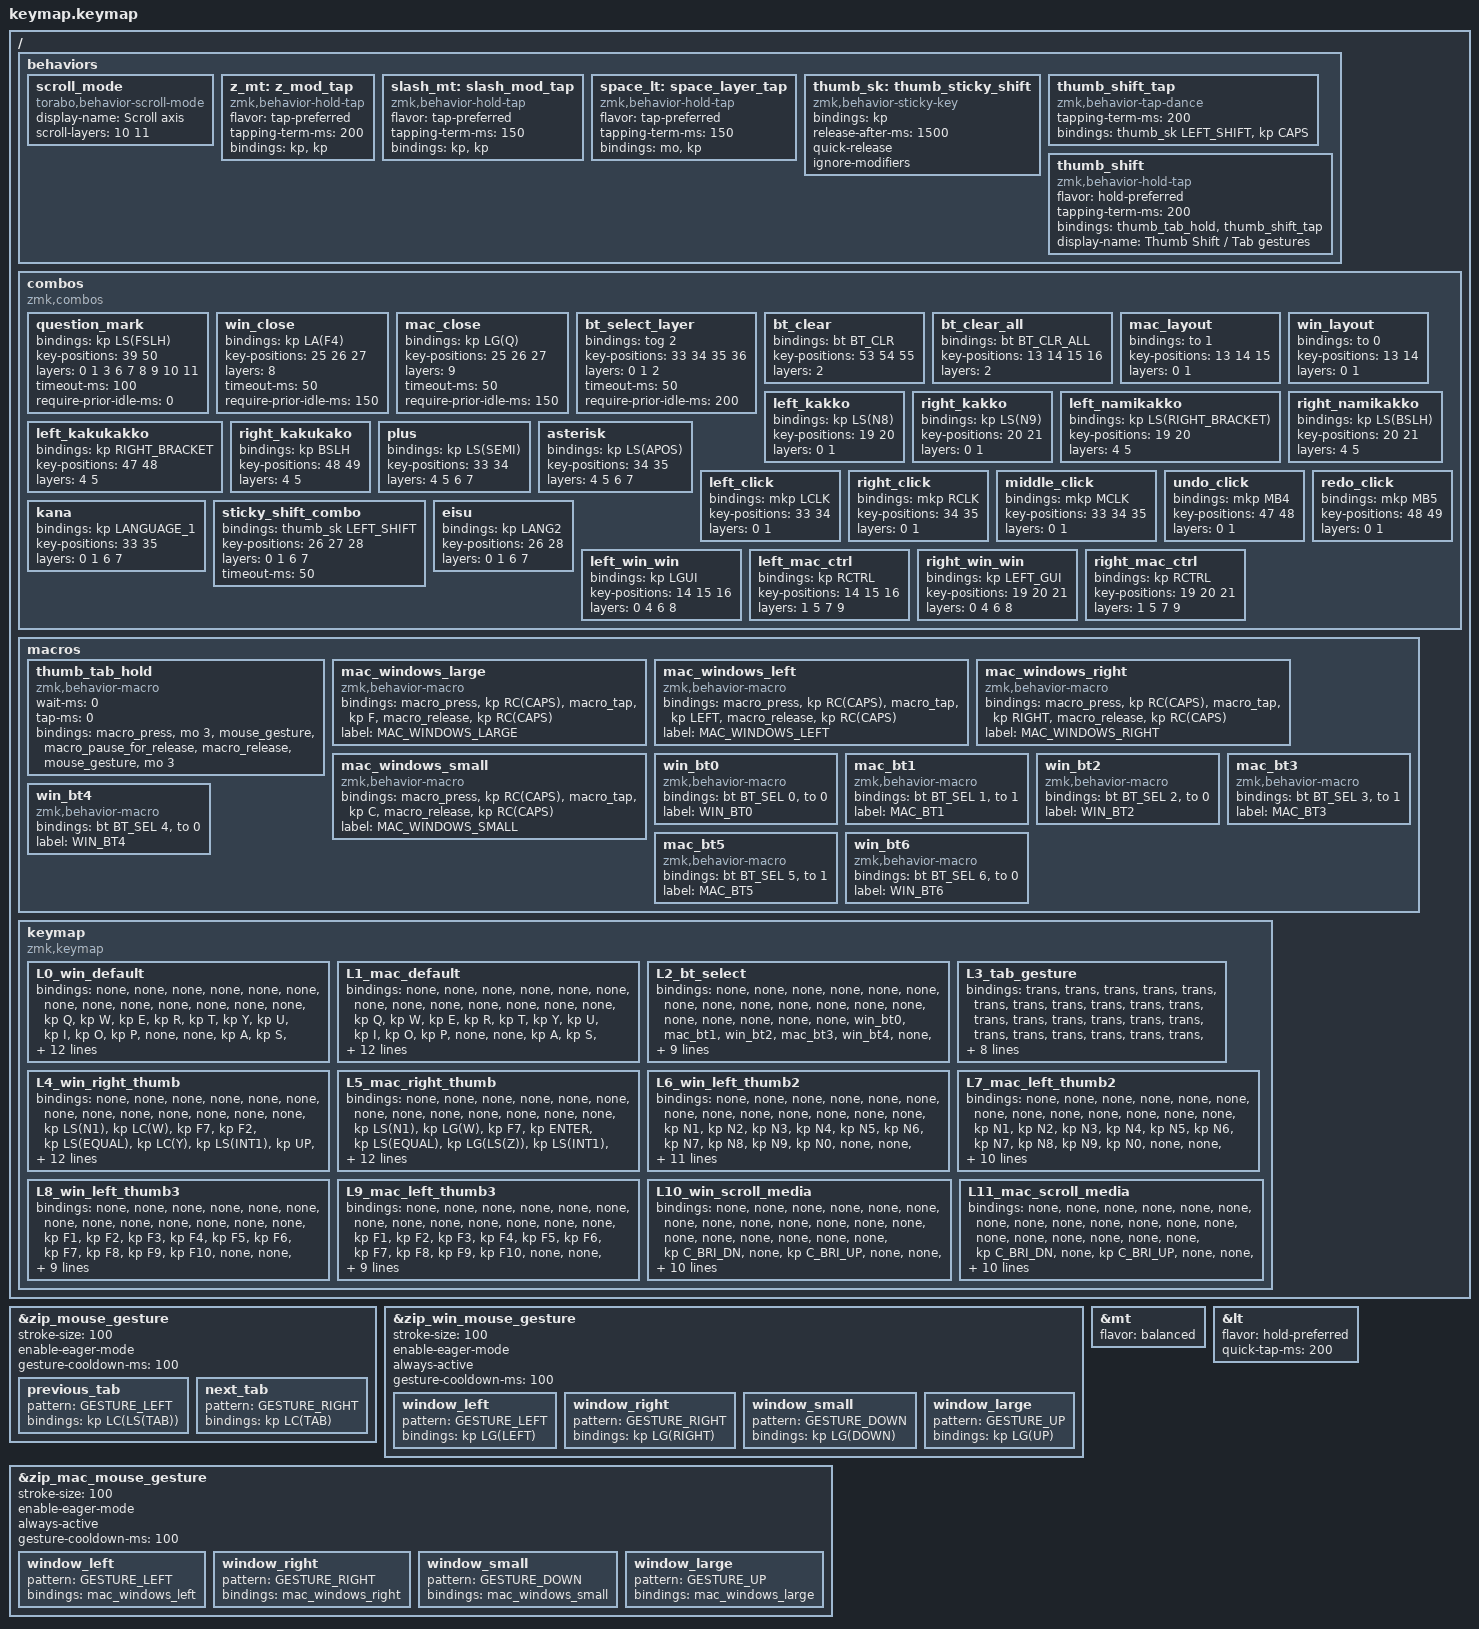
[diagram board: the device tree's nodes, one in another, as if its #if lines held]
#include <mouse-gesture.dtsi>
#include <zephyr/dt-bindings/input/input-event-codes.h>
#include <behaviors.dtsi>
#include <dt-bindings/zmk/bt.h>
#include <dt-bindings/zmk/keys.h>
#include <dt-bindings/zmk/pointing.h>

#if defined(TORABO_TSUKI_LP_INPUT_HIRES_DIAL)
#include <behaviors/hires_dial.dtsi>
#endif

#define FUNC         0x36  // Function

/ {
    behaviors {
        scroll_mode: scroll_mode {
            compatible = "torabo,behavior-scroll-mode";
            #binding-cells = <1>;
            display-name = "Scroll axis";
            scroll-layers = <10 11>;
        };

        z_mt: z_mod_tap {
            compatible = "zmk,behavior-hold-tap";
            #binding-cells = <2>;
            flavor = "tap-preferred";
            tapping-term-ms = <200>;
            bindings = <&kp>, <&kp>;
        };

        slash_mt: slash_mod_tap {
            compatible = "zmk,behavior-hold-tap";
            #binding-cells = <2>;
            flavor = "tap-preferred";
            tapping-term-ms = <150>;
            bindings = <&kp>, <&kp>;
        };

        space_lt: space_layer_tap {
            compatible = "zmk,behavior-hold-tap";
            #binding-cells = <2>;
            flavor = "tap-preferred";
            tapping-term-ms = <150>;
            bindings = <&mo>, <&kp>;
        };

        thumb_sk: thumb_sticky_shift {
            compatible = "zmk,behavior-sticky-key";
            #binding-cells = <1>;
            bindings = <&kp>;
            release-after-ms = <1500>;
            quick-release;
            ignore-modifiers;
        };

        thumb_shift_tap: thumb_shift_tap {
            compatible = "zmk,behavior-tap-dance";
            #binding-cells = <0>;
            tapping-term-ms = <200>;
            bindings = <&thumb_sk LEFT_SHIFT>, <&kp CAPS>;
        };

        thumb_shift: thumb_shift {
            compatible = "zmk,behavior-hold-tap";
            #binding-cells = <2>;
            flavor = "hold-preferred";
            tapping-term-ms = <200>;
            // Both child behaviors take no parameters; keymap arguments are ignored.
            // Keep hold-tap outside tap-dance so tab gestures need only 200ms.
            bindings = <&thumb_tab_hold>, <&thumb_shift_tap>;
            display-name = "Thumb Shift / Tab gestures";
        };
    };

    combos {
        compatible = "zmk,combos";

        question_mark {
            bindings = <&kp LS(FSLH)>;
            key-positions = <39 50>;
            layers = <0 1 3 6 7 8 9 10 11>;
            timeout-ms = <100>;
            // Allow the combo during typing; keep the normal Z hold-tap unchanged.
            require-prior-idle-ms = <0>;
        };

        win_close {
            bindings = <&kp LA(F4)>;
            key-positions = <25 26 27>;
            layers = <8>;
            timeout-ms = <50>;
            require-prior-idle-ms = <150>;
        };

        mac_close {
            bindings = <&kp LG(Q)>;
            key-positions = <25 26 27>;
            layers = <9>;
            timeout-ms = <50>;
            require-prior-idle-ms = <150>;
        };

        bt_select_layer {
            bindings = <&tog 2>;
            key-positions = <33 34 35 36>;
            layers = <0 1 2>;
            timeout-ms = <50>;
            require-prior-idle-ms = <200>;
        };

        bt_clear {
            bindings = <&bt BT_CLR>;
            key-positions = <53 54 55>;
            layers = <2>;
        };

        bt_clear_all {
            bindings = <&bt BT_CLR_ALL>;
            key-positions = <13 14 15 16>;
            layers = <2>;
        };

        mac_layout {
            bindings = <&to 1>;
            key-positions = <13 14 15>;
            layers = <0 1>;
        };

        win_layout {
            bindings = <&to 0>;
            key-positions = <13 14>;
            layers = <0 1>;
        };

        left_kakko {
            bindings = <&kp LS(N8)>;
            key-positions = <19 20>;
            layers = <0 1>;
        };

        right_kakko {
            bindings = <&kp LS(N9)>;
            key-positions = <20 21>;
            layers = <0 1>;
        };

        left_namikakko {
            bindings = <&kp LS(RIGHT_BRACKET)>;
            key-positions = <19 20>;
            layers = <4 5>;
        };

        right_namikakko {
            bindings = <&kp LS(BSLH)>;
            key-positions = <20 21>;
            layers = <4 5>;
        };

        left_kakukakko {
            bindings = <&kp RIGHT_BRACKET>;
            key-positions = <47 48>;
            layers = <4 5>;
        };

        right_kakukako {
            bindings = <&kp BSLH>;
            key-positions = <48 49>;
            layers = <4 5>;
        };

        //        semicolon {
        //            bindings = <&kp SEMI>;
        //            key-positions = <33 34>;
        //            layers = <10 11>;
        //        };
        //
        //        colon {
        //            bindings = <&kp APOS>;
        //            key-positions = <34 35>;
        //            layers = <10 11>;
        //        };

        plus {
            bindings = <&kp LS(SEMI)>;
            key-positions = <33 34>;
            layers = <4 5 6 7>;
        };

        asterisk {
            bindings = <&kp LS(APOS)>;
            key-positions = <34 35>;
            layers = <4 5 6 7>;
        };

        left_click {
            bindings = <&mkp LCLK>;
            key-positions = <33 34>;
            layers = <0 1>;
        };

        right_click {
            bindings = <&mkp RCLK>;
            key-positions = <34 35>;
            layers = <0 1>;
        };

        middle_click {
            bindings = <&mkp MCLK>;
            key-positions = <33 34 35>;
            layers = <0 1>;
        };

        undo_click {
            bindings = <&mkp MB4>;
            key-positions = <47 48>;
            layers = <0 1>;
        };

        redo_click {
            bindings = <&mkp MB5>;
            key-positions = <48 49>;
            layers = <0 1>;
        };

        kana {
            bindings = <&kp LANGUAGE_1>;
            key-positions = <33 35>;
            layers = <0 1 6 7>;
        };

        sticky_shift_combo {
            bindings = <&thumb_sk LEFT_SHIFT>;
            key-positions = <26 27 28>;
            layers = <0 1 6 7>;
            timeout-ms = <50>;
        };

        eisu {
            bindings = <&kp LANG2>;
            key-positions = <26 28>;
            layers = <0 1 6 7>;
        };

        left_win_win {
            bindings = <&kp LGUI>;
            key-positions = <14 15 16>;
            layers = <0 4 6 8>;
        };

        left_mac_ctrl {
            bindings = <&kp RCTRL>;
            key-positions = <14 15 16>;
            layers = <1 5 7 9>;
        };

        right_win_win {
            bindings = <&kp LEFT_GUI>;
            key-positions = <19 20 21>;
            layers = <0 4 6 8>;
        };

        right_mac_ctrl {
            bindings = <&kp RCTRL>;
            key-positions = <19 20 21>;
            layers = <1 5 7 9>;
        };
    };

    macros {
        thumb_tab_hold: thumb_tab_hold {
            compatible = "zmk,behavior-macro";
            #binding-cells = <0>;
            wait-ms = <0>;
            tap-ms = <0>;
            bindings =
                <&macro_press>,
                <&mo 3>,
                <&mouse_gesture>,
                <&macro_pause_for_release>,
                <&macro_release>,
                <&mouse_gesture>,
                <&mo 3>;
        };

        mac_windows_large: mac_windows_large {
            compatible = "zmk,behavior-macro";
            #binding-cells = <0>;
            bindings =
                <&macro_press>,
                <&kp RC(CAPS)>,
                <&macro_tap>,
                <&kp F>,
                <&macro_release>,
                <&kp RC(CAPS)>;

            label = "MAC_WINDOWS_LARGE";
        };

        mac_windows_left: mac_windows_left {
            compatible = "zmk,behavior-macro";
            #binding-cells = <0>;
            bindings =
                <&macro_press>,
                <&kp RC(CAPS)>,
                <&macro_tap>,
                <&kp LEFT>,
                <&macro_release>,
                <&kp RC(CAPS)>;

            label = "MAC_WINDOWS_LEFT";
        };

        mac_windows_right: mac_windows_right {
            compatible = "zmk,behavior-macro";
            #binding-cells = <0>;
            bindings =
                <&macro_press>,
                <&kp RC(CAPS)>,
                <&macro_tap>,
                <&kp RIGHT>,
                <&macro_release>,
                <&kp RC(CAPS)>;

            label = "MAC_WINDOWS_RIGHT";
        };

        mac_windows_small: mac_windows_small {
            compatible = "zmk,behavior-macro";
            #binding-cells = <0>;
            bindings =
                <&macro_press>,
                <&kp RC(CAPS)>,
                <&macro_tap>,
                <&kp C>,
                <&macro_release>,
                <&kp RC(CAPS)>;

            label = "MAC_WINDOWS_SMALL";
        };

        win_bt0: win_bt0 {
            compatible = "zmk,behavior-macro";
            #binding-cells = <0>;
            bindings = <&bt BT_SEL 0 &to 0>;
            label = "WIN_BT0";
        };

        mac_bt1: mac_bt1 {
            compatible = "zmk,behavior-macro";
            #binding-cells = <0>;
            bindings = <&bt BT_SEL 1 &to 1>;
            label = "MAC_BT1";
        };

        win_bt2: win_bt2 {
            compatible = "zmk,behavior-macro";
            #binding-cells = <0>;
            bindings = <&bt BT_SEL 2 &to 0>;
            label = "WIN_BT2";
        };

        mac_bt3: mac_bt3 {
            compatible = "zmk,behavior-macro";
            #binding-cells = <0>;
            bindings = <&bt BT_SEL 3 &to 1>;
            label = "MAC_BT3";
        };

        win_bt4: win_bt4 {
            compatible = "zmk,behavior-macro";
            #binding-cells = <0>;
            bindings = <&bt BT_SEL 4 &to 0>;
            label = "WIN_BT4";
        };

        mac_bt5: mac_bt5 {
            compatible = "zmk,behavior-macro";
            #binding-cells = <0>;
            bindings = <&bt BT_SEL 5 &to 1>;
            label = "MAC_BT5";
        };

        win_bt6: win_bt6 {
            compatible = "zmk,behavior-macro";
            #binding-cells = <0>;
            bindings = <&bt BT_SEL 6 &to 0>;
            label = "WIN_BT6";
        };
    };

    keymap {
        compatible = "zmk,keymap";

        L0_win_default {
            bindings = <
&none  &none             &none     &none     &none                &none                                    &none       &none  &none      &none     &none                 &none
&none  &kp Q             &kp W     &kp E     &kp R                &kp T                                    &kp Y       &kp U  &kp I      &kp O     &kp P                 &none
&none  &kp A             &kp S     &kp D     &kp F                &kp G        &none        &none          &kp H       &kp J  &kp K      &kp L     &lt 10 ENTER          &none
&none  &z_mt LEFT_SHIFT Z  &kp X     &kp C     &kp V                &kp B        &kp ESC      &kp DELETE     &kp N       &kp M  &kp COMMA  &kp DOT   &slash_mt RIGHT_SHIFT FSLH  &none
&none  &kp LCTRL         &kp LGUI  &kp LALT  &thumb_shift 0 0  &space_lt 6 SPACE  &lt 8 GRAVE  &mt RCTRL TAB  &lt 4 BSPC  &none  &none      &kp HOME  &kp END               &none
#if defined(TORABO_TSUKI_LP_KSCAN_4_DIRECTION_SWITCH)
&msc SCRL_UP &msc SCRL_DOWN &msc SCRL_LEFT &msc SCRL_RIGHT &mkp MCLK
#elif defined(TORABO_TSUKI_LP_INPUT_HIRES_DIAL)
&mkp MCLK
#endif
            >;
        };

        L1_mac_default {
            bindings = <
&none  &none             &none     &none              &none                &none                                       &none       &none  &none      &none         &none                 &none
&none  &kp Q             &kp W     &kp E              &kp R                &kp T                                       &kp Y       &kp U  &kp I      &kp O         &kp P                 &none
&none  &kp A             &kp S     &kp D              &kp F                &kp G        &none        &none             &kp H       &kp J  &kp K      &kp L         &lt 11 ENTER          &none
&none  &z_mt LEFT_SHIFT Z  &kp X     &kp C              &kp V                &kp B        &kp ESC      &kp LG(BSPC)      &kp N       &kp M  &kp COMMA  &kp DOT       &slash_mt RIGHT_SHIFT FSLH  &none
&none  &kp LGUI          &kp LALT  &kp RIGHT_CONTROL  &thumb_shift 0 0  &space_lt 7 SPACE  &lt 9 LCTRL  &mt LEFT_GUI TAB  &lt 5 BSPC  &none  &none      &kp LG(LEFT)  &kp LG(RIGHT)         &none
#if defined(TORABO_TSUKI_LP_KSCAN_4_DIRECTION_SWITCH)
&msc SCRL_UP &msc SCRL_DOWN &msc SCRL_LEFT &msc SCRL_RIGHT &mkp MCLK
#elif defined(TORABO_TSUKI_LP_INPUT_HIRES_DIAL)
&mkp MCLK
#endif
            >;
        };

        // Latched Bluetooth management: selection returns, disconnect/clear stay here.
        // No transparent bindings: unrelated keys cannot type or click here.
        L2_bt_select {
            bindings = <
&none  &none  &none  &none  &none  &none                  &none     &none     &none     &none     &none     &none
&none  &none  &none  &none  &none  &none                  &win_bt0  &mac_bt1  &win_bt2  &mac_bt3  &win_bt4  &none
&none  &bt BT_DISC 0  &bt BT_DISC 1  &bt BT_DISC 2  &bt BT_DISC 3  &bt BT_DISC 4  &none &none &mac_bt5 &win_bt6 &none &none &tog 2 &none
&none  &bt BT_DISC 5  &bt BT_DISC 6  &none  &none  &none  &tog 2  &none   &none    &none     &none     &none     &none     &none
&none  &none  &none  &none  &none  &none  &none   &none   &none    &none     &none     &none     &none     &none
#if defined(TORABO_TSUKI_LP_KSCAN_4_DIRECTION_SWITCH)
&none &none &none &none &none
#elif defined(TORABO_TSUKI_LP_INPUT_HIRES_DIAL)
&none
#endif
            >;
        };

        // Thumb hold enables tab gestures; typing inherits the active OS/layers.
        L3_tab_gesture {
            bindings = <
&trans &trans &trans &trans &trans &trans             &trans &trans &trans &trans &trans &trans
&trans &trans &trans &trans &trans &trans             &trans &trans &trans &trans &trans &trans
&trans &trans &trans &trans &trans &trans &trans &trans &trans &trans &trans &trans &trans &trans
&trans &trans &trans &trans &trans &trans &trans &trans &trans &trans &trans &trans &trans &trans
&trans &trans &trans &trans &trans &trans &trans &trans &trans &trans &trans &trans &trans &trans
#if defined(TORABO_TSUKI_LP_KSCAN_4_DIRECTION_SWITCH)
&trans &trans &trans &trans &trans
#elif defined(TORABO_TSUKI_LP_INPUT_HIRES_DIAL)
&trans
#endif
            >;
        };

        L4_win_right_thumb {
            bindings = <
&none  &none                 &none       &none       &none      &none                                       &none       &none         &none     &none      &none            &none
&none  &kp LS(N1)            &kp LC(W)   &kp F7      &kp F2     &kp LS(EQUAL)                               &kp LC(Y)   &kp LS(INT1)  &kp UP    &kp MINUS  &kp LS(N5)       &none
&none  &kp LS(N6)            &kp LS(N7)  &kp LS(N2)  &kp BSPC   &kp LBKT       &none              &none     &kp EQUAL   &kp LEFT      &kp DOWN  &kp RIGHT  &kp F10          &none
&none  &mt LEFT_SHIFT LC(Z)  &kp LC(X)   &kp LC(C)   &kp LC(V)  &kp INT3       &kp RIGHT_BRACKET  &kp BSLH  &kp LS(N3)  &kp LS(N4)    &kp SEMI  &kp APOS   &kp RIGHT_SHIFT  &none
&none  &trans                &trans      &trans      &trans     &kp LS(SPACE)  &trans             &trans    &trans      &none         &none     &trans     &trans           &none
#if defined(TORABO_TSUKI_LP_KSCAN_4_DIRECTION_SWITCH)
&msc SCRL_UP &msc SCRL_DOWN &msc SCRL_LEFT &msc SCRL_RIGHT &mkp MCLK
#elif defined(TORABO_TSUKI_LP_INPUT_HIRES_DIAL)
&mkp MCLK
#endif
            >;
        };

        L5_mac_right_thumb {
            bindings = <
&none  &none                 &none       &none       &none      &none                                       &none          &none         &none     &none      &none            &none
&none  &kp LS(N1)            &kp LG(W)   &kp F7      &kp ENTER     &kp LS(EQUAL)                               &kp LG(LS(Z))  &kp LS(INT1)  &kp UP    &kp MINUS  &kp LS(N5)       &none
&none  &kp LS(N6)            &kp LS(N7)  &kp LS(N2)  &kp BSPC   &kp LBKT       &none              &none     &kp EQUAL      &kp LEFT      &kp DOWN  &kp RIGHT  &kp F10          &none
&none  &mt LEFT_SHIFT LG(Z)  &kp LG(X)   &kp LG(C)   &kp LG(V)  &kp INT3       &kp RIGHT_BRACKET  &kp BSLH  &kp LS(N3)     &kp LS(N4)    &kp SEMI  &kp APOS   &kp RIGHT_SHIFT  &none
&none  &trans                &trans      &trans      &trans     &kp LS(SPACE)  &trans             &trans    &trans         &none         &none     &trans     &trans           &none
#if defined(TORABO_TSUKI_LP_KSCAN_4_DIRECTION_SWITCH)
&msc SCRL_UP &msc SCRL_DOWN &msc SCRL_LEFT &msc SCRL_RIGHT &mkp MCLK
#elif defined(TORABO_TSUKI_LP_INPUT_HIRES_DIAL)
&mkp MCLK
#endif
            >;
        };

        L6_win_left_thumb2 {
            bindings = <
&none  &none         &none             &none         &none              &none                       &none              &none   &none   &none   &none         &none
&none  &kp N1        &kp N2            &kp N3        &kp N4             &kp N5                      &kp N6             &kp N7  &kp N8  &kp N9  &kp N0        &none
&none  &kp LC(LBKT)  &kp LS(TAB)       &kp LEFT_ALT  &kp TAB            &trans  &none   &none       &kp MINUS          &kp N4  &kp N5  &kp N6  &trans        &none
&none  &trans        &kp LG(LC(LEFT))  &kp LG(TAB)   &kp LG(LC(RIGHT))  &trans  &trans  &kp PERIOD  &kp LS(SEMICOLON)  &kp N1  &kp N2  &kp N3  &kp SLASH     &none
&none  &trans        &trans            &trans        &trans             &trans  &trans  &trans      &trans             &none   &none   &kp N0  &kp LS(APOS)  &none
#if defined(TORABO_TSUKI_LP_KSCAN_4_DIRECTION_SWITCH)
&msc SCRL_UP &msc SCRL_DOWN &msc SCRL_LEFT &msc SCRL_RIGHT &mkp MCLK
#elif defined(TORABO_TSUKI_LP_INPUT_HIRES_DIAL)
&mkp MCLK
#endif
            >;
        };

        L7_mac_left_thumb2 {
            bindings = <
&none  &none         &none         &none         &none          &none                       &none              &none   &none   &none   &none         &none
&none  &kp N1        &kp N2        &kp N3        &kp N4         &kp N5                      &kp N6             &kp N7  &kp N8  &kp N9  &kp N0        &none
&none  &kp RC(LBKT)  &kp LSHIFT    &kp LEFT_ALT  &kp TAB        &trans  &none   &none       &kp MINUS          &kp N4  &kp N5  &kp N6  &trans        &none
&none  &trans        &kp RC(LEFT)  &kp RC(UP)    &kp RC(RIGHT)  &trans  &trans  &kp PERIOD  &kp LS(SEMICOLON)  &kp N1  &kp N2  &kp N3  &kp SLASH     &none
&none  &trans        &trans        &trans        &trans         &trans  &trans  &trans      &trans             &none   &none   &kp N0  &kp LS(APOS)  &none
#if defined(TORABO_TSUKI_LP_KSCAN_4_DIRECTION_SWITCH)
&msc SCRL_UP &msc SCRL_DOWN &msc SCRL_LEFT &msc SCRL_RIGHT &mkp MCLK
#elif defined(TORABO_TSUKI_LP_INPUT_HIRES_DIAL)
&mkp MCLK
#endif
            >;
        };

        L8_win_left_thumb3 {
            bindings = <
&none  &none    &none    &none      &none   &none                   &none       &none   &none   &none     &none            &none
&none  &kp F1   &kp F2   &kp F3     &kp F4  &kp F5                  &kp F6      &kp F7  &kp F8  &kp F9    &kp F10          &none
&none  &kp F11  &kp F12  &kp LG(E)  &trans  &trans  &none   &none   &none       &trans  &trans  &kp CAPS  &kp PRINTSCREEN  &none
&none  &trans   &trans   &trans     &trans  &trans  &trans  &trans  &trans      &trans  &trans  &trans    &trans           &none
&none  &trans   &trans   &trans     &trans  &trans  &trans  &trans  &trans      &none   &none   &trans    &trans           &none
#if defined(TORABO_TSUKI_LP_KSCAN_4_DIRECTION_SWITCH)
&msc SCRL_UP &msc SCRL_DOWN &msc SCRL_LEFT &msc SCRL_RIGHT &mkp MCLK
#elif defined(TORABO_TSUKI_LP_INPUT_HIRES_DIAL)
&mkp MCLK
#endif
            >;
        };

        L9_mac_left_thumb3 {
            bindings = <
&none  &none    &none    &none   &none   &none                   &none      &none   &none   &none     &none           &none
&none  &kp F1   &kp F2   &kp F3  &kp F4  &kp F5                  &kp F6     &kp F7  &kp F8  &kp F9    &kp F10         &none
&none  &kp F11  &kp F12  &trans  &trans  &trans  &none   &none   &none      &trans  &trans  &kp CAPS  &kp LG(LS(N4))  &none
&none  &trans   &trans   &trans  &trans  &trans  &trans  &trans  &trans     &trans  &trans  &trans    &trans          &none
&none  &trans   &trans   &trans  &trans  &trans  &trans  &trans  &trans     &none   &none   &trans    &trans          &none
#if defined(TORABO_TSUKI_LP_KSCAN_4_DIRECTION_SWITCH)
&msc SCRL_UP &msc SCRL_DOWN &msc SCRL_LEFT &msc SCRL_RIGHT &mkp MCLK
#elif defined(TORABO_TSUKI_LP_INPUT_HIRES_DIAL)
&mkp MCLK
#endif
            >;
        };

        L10_win_scroll_media {
            bindings = <
&none  &none          &none          &none          &none          &none                                    &none     &none         &none       &none         &none     &none
&none  &none          &none          &none          &none          &none                                    &none     &kp C_BRI_DN  &none       &kp C_BRI_UP  &none     &none
&none  &trans        &trans        &trans        &trans        &trans        &none   &none             &scroll_mode 0  &scroll_mode 1  &scroll_mode 2  &kp LCTRL     &trans    &none
&none  &trans         &trans         &trans         &trans         &trans         &trans  &trans            &trans    &kp C_VOL_DN  &kp C_MUTE  &kp C_VOL_UP  &trans    &none
&none  &trans         &trans         &trans         &trans         &trans         &trans  &kp C_PLAY_PAUSE  &trans    &none         &none       &trans        &trans    &none
#if defined(TORABO_TSUKI_LP_KSCAN_4_DIRECTION_SWITCH)
&msc SCRL_UP &msc SCRL_DOWN &msc SCRL_LEFT &msc SCRL_RIGHT &mkp MCLK
#elif defined(TORABO_TSUKI_LP_INPUT_HIRES_DIAL)
&mkp MCLK
#endif
            >;
        };

        L11_mac_scroll_media {
            bindings = <
&none  &none          &none          &none          &none          &none                                    &none     &none         &none       &none         &none     &none
&none  &none          &none          &none          &none          &none                                    &none     &kp C_BRI_DN  &none       &kp C_BRI_UP  &none     &none
&none  &trans        &trans        &trans        &trans        &trans        &none   &none             &scroll_mode 0  &scroll_mode 1  &scroll_mode 2  &kp RCTRL     &trans    &none
&none  &trans         &trans         &trans         &trans         &trans         &trans  &trans            &trans    &kp C_VOL_DN  &kp C_MUTE  &kp C_VOL_UP  &trans    &none
&none  &trans         &trans         &trans         &trans         &trans         &trans  &kp C_PLAY_PAUSE  &trans    &none         &none       &trans        &trans    &none
#if defined(TORABO_TSUKI_LP_KSCAN_4_DIRECTION_SWITCH)
&msc SCRL_UP &msc SCRL_DOWN &msc SCRL_LEFT &msc SCRL_RIGHT &mkp MCLK
#elif defined(TORABO_TSUKI_LP_INPUT_HIRES_DIAL)
&mkp MCLK
#endif
            >;
        };
    };
};

&zip_mouse_gesture {
    stroke-size = <100>;
    enable-eager-mode;
    // Activation via thumb_tab_hold resets partial strokes between holds.
    gesture-cooldown-ms = <100>;

    previous_tab {
        pattern = <GESTURE_LEFT>;
        bindings = <&kp LC(LS(TAB))>;
    };

    next_tab {
        pattern = <GESTURE_RIGHT>;
        bindings = <&kp LC(TAB)>;
    };
};

&zip_win_mouse_gesture {
    stroke-size = <100>;
    enable-eager-mode;
    always-active;
    gesture-cooldown-ms = <100>;

    window_left {
        pattern = <GESTURE_LEFT>;
        bindings = <&kp LG(LEFT)>;
    };

    window_right {
        pattern = <GESTURE_RIGHT>;
        bindings = <&kp LG(RIGHT)>;
    };

    window_small {
        pattern = <GESTURE_DOWN>;
        bindings = <&kp LG(DOWN)>;
    };

    window_large {
        pattern = <GESTURE_UP>;
        bindings = <&kp LG(UP)>;
    };
};

&zip_mac_mouse_gesture {
    stroke-size = <100>;
    enable-eager-mode;
    always-active;
    gesture-cooldown-ms = <100>;

    window_left {
        pattern = <GESTURE_LEFT>;
        bindings = <&mac_windows_left>;
    };

    window_right {
        pattern = <GESTURE_RIGHT>;
        bindings = <&mac_windows_right>;
    };

    window_small {
        pattern = <GESTURE_DOWN>;
        bindings = <&mac_windows_small>;
    };

    window_large {
        pattern = <GESTURE_UP>;
        bindings = <&mac_windows_large>;
    };
};

&mt { flavor = "balanced"; };

&lt {
    flavor = "hold-preferred";
    quick-tap-ms = <200>;
};

#if defined(TORABO_TSUKI_LP_INPUT_HIRES_DIAL)
&{/keymap/L0_win_default} {
    sensor-bindings = <&hires_dial_scroll 1 1>;
};

&{/keymap/L1_mac_default} {
    sensor-bindings = <&hires_dial_scroll 10 1>;
};

#endif
